AUTOSAR XML (schema 4-2-2)
package /Acme/Types
  base type Octet: category=FIXED_LENGTH, base-type-size=8, base-type-encoding=NONE, native-declaration=uint8
  impl type Level: category=VALUE, base-type=Octet
  impl type Clash: category=VALUE, base-type=Octet
  impl type LocalAlias: implementation-data-type=RemoteBase
package /Acme/Constants
  constant specification CZero: value-spec=0
package /Acme/Interfaces
  sender receiver interface IStatus
    4 x data:
      value: type=RemoteValue, init-value=constant-reference=CZero
      level: type=Level
      aliased: type=LocalAlias
      clashing: type=Clash
  client server interface IService
    operation Run
      arg request: type=RemoteArg, direction=IN
      arg clash: type=Clash, direction=OUT
    operation Stop
      arg request: type=RemoteArg, direction=IN
    operation Measure
      arg phys: type=RemotePhys, direction=OUT
  sender receiver interface IAbandoned
    data first: type=OnlyAbandoned
    data second: type=Octet
  mode switch interface IDeclaredMode
package /Acme/Components
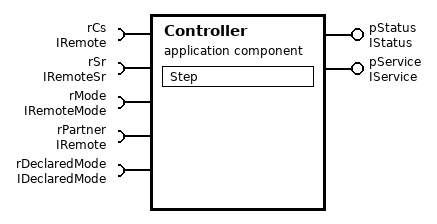
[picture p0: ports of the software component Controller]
  application sw component type Controller
    4 x require port:
      rCs: required-interface=IRemote
      rSr: nonqueued-receiver-com-spec{data-element=signal, init-value=constant-reference=CZero}, required-interface=IRemoteSr
      rMode: required-interface=IRemoteMode
      rPartner: required-interface=IRemote
    provide port pStatus: provided-interface=IStatus
    provide port pService: provided-interface=IService
    require port rDeclaredMode: required-interface=IDeclaredMode
    behavior ControllerBehavior: handle-termination-and-restart=NO-SUPPORT
      runnable Step
        data-receive-point-by-arguments:
          access readSignal: accessed-variable=rSr.signal
        sync call callRun: operation=rCs.Run, timeout=0
package /Acme/Compositions
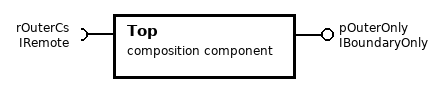
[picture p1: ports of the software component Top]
  composition sw component type Top
    require port rOuterCs: required-interface=IRemote
    provide port pOuterOnly: provided-interface=IBoundaryOnly
    component ctl: type=Controller
